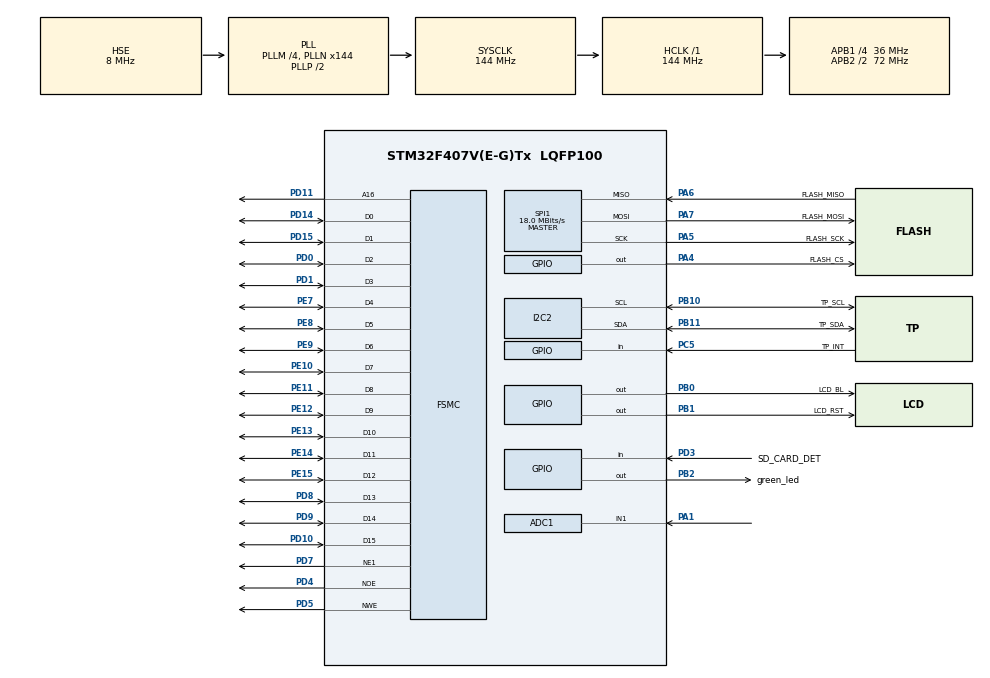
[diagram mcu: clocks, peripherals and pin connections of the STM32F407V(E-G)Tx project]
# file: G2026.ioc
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ADC1.Channel-1\#ChannelRegularConversion=ADC_CHANNEL_1
ADC1.DMAContinuousRequests=ENABLE
ADC1.ExternalTrigConv=ADC_EXTERNALTRIGCONV_T8_TRGO
ADC1.NbrOfConversionFlag=1
ADC1.Rank-1\#ChannelRegularConversion=1
ADC1.SamplingTime-1\#ChannelRegularConversion=ADC_SAMPLETIME_3CYCLES
ADC1.master=1
Dma.ADC1.0.Direction=DMA_PERIPH_TO_MEMORY
Dma.ADC1.0.FIFOMode=DMA_FIFOMODE_DISABLE
Dma.ADC1.0.Instance=DMA2_Stream0
Dma.ADC1.0.MemDataAlignment=DMA_MDATAALIGN_HALFWORD
Dma.ADC1.0.MemInc=DMA_MINC_ENABLE
Dma.ADC1.0.Mode=DMA_CIRCULAR
Dma.ADC1.0.PeriphDataAlignment=DMA_PDATAALIGN_HALFWORD
Dma.ADC1.0.PeriphInc=DMA_PINC_DISABLE
Dma.ADC1.0.Priority=DMA_PRIORITY_HIGH
Dma.Request0=ADC1
FREERTOS.Tasks01=defaultTask,24,256,StartDefaultTask,Default,NULL,Dynamic,NULL,NULL
FREERTOS.configTOTAL_HEAP_SIZE=4096
FSMC.AddressSetupTime1=2
FSMC.BusTurnAroundDuration1=0
FSMC.DataSetupTime1=8
FSMC.WriteOperation1=FSMC_WRITE_OPERATION_ENABLE
I2C2.I2C_Mode=I2C_Standard
Mcu.Family=STM32F4
Mcu.Name=STM32F407V(E-G)Tx
Mcu.Package=LQFP100
NVIC.DMA2_Stream0_IRQn=true\:5\:0\:false\:false\:true\:true\:false\:true\:true
NVIC.PriorityGroup=NVIC_PRIORITYGROUP_4
NVIC.TIM6_DAC_IRQn=true\:15\:0\:false\:false\:true\:false\:true\:true\:true
NVIC.TimeBase=TIM6_DAC_IRQn
NVIC.TimeBaseIP=TIM6
PA1.Signal=ADCx_IN1
PA13.GPIO_Label=SWDIO
PA13.Mode=Serial_Wire
PA13.Signal=SYS_JTMS-SWDIO
PA14.GPIO_Label=SWCLK
PA14.Mode=Serial_Wire
PA14.Signal=SYS_JTCK-SWCLK
PA4.GPIO_Label=FLASH_CS
PA4.PinState=GPIO_PIN_SET
PA4.Signal=GPIO_Output
PA5.GPIO_Label=FLASH_SCK
PA5.Mode=Full_Duplex_Master
PA5.Signal=SPI1_SCK
PA6.GPIO_Label=FLASH_MISO
PA6.Mode=Full_Duplex_Master
PA6.Signal=SPI1_MISO
PA7.GPIO_Label=FLASH_MOSI
PA7.Mode=Full_Duplex_Master
PA7.Signal=SPI1_MOSI
PB0.GPIO_Label=LCD_BL
PB0.PinState=GPIO_PIN_RESET
PB0.Signal=GPIO_Output
PB1.GPIO_Label=LCD_RST
PB1.PinState=GPIO_PIN_SET
PB1.Signal=GPIO_Output
PB10.GPIO_Label=TP_SCL
PB10.Mode=I2C
PB10.Signal=I2C2_SCL
PB11.GPIO_Label=TP_SDA
PB11.Mode=I2C
PB11.Signal=I2C2_SDA
PB2.GPIO_Label=green_led
PB2.PinState=GPIO_PIN_RESET
PB2.Signal=GPIO_Output
PC14-OSC32_IN.GPIO_Label=LSE_IN
PC14-OSC32_IN.Mode=LSE-External-Oscillator
PC14-OSC32_IN.Signal=RCC_OSC32_IN
PC15-OSC32_OUT.GPIO_Label=LSE_OUT
PC15-OSC32_OUT.Mode=LSE-External-Oscillator
PC15-OSC32_OUT.Signal=RCC_OSC32_OUT
PC5.GPIO_Label=TP_INT
PC5.GPIO_PuPd=GPIO_PULLUP
PC5.Signal=GPIO_Input
PD0.Mode=16b-d1
PD0.Signal=FSMC_D2
PD1.Mode=16b-d1
PD1.Signal=FSMC_D3
PD10.Mode=16b-d1
PD10.Signal=FSMC_D15
PD11.Mode=A16_1
PD11.Signal=FSMC_A16
PD14.Mode=16b-d1
PD14.Signal=FSMC_D0
PD15.Mode=16b-d1
PD15.Signal=FSMC_D1
PD3.GPIO_Label=SD_CARD_DET
PD3.GPIO_PuPd=GPIO_PULLUP
PD3.Signal=GPIO_Input
PD4.Mode=Lcd1
PD4.Signal=FSMC_NOE
PD5.Mode=Lcd1
PD5.Signal=FSMC_NWE
PD7.Mode=NorPsramChipSelect1_1
PD7.Signal=FSMC_NE1
PD8.Mode=16b-d1
PD8.Signal=FSMC_D13
PD9.Mode=16b-d1
PD9.Signal=FSMC_D14
PE10.Mode=16b-d1
PE10.Signal=FSMC_D7
PE11.Mode=16b-d1
PE11.Signal=FSMC_D8
PE12.Mode=16b-d1
PE12.Signal=FSMC_D9
PE13.Mode=16b-d1
PE13.Signal=FSMC_D10
PE14.Mode=16b-d1
PE14.Signal=FSMC_D11
PE15.Mode=16b-d1
PE15.Signal=FSMC_D12
PE7.Mode=16b-d1
PE7.Signal=FSMC_D4
PE8.Mode=16b-d1
PE8.Signal=FSMC_D5
PE9.Mode=16b-d1
PE9.Signal=FSMC_D6
PH0-OSC_IN.GPIO_Label=HSE_IN
PH0-OSC_IN.Mode=HSE-External-Oscillator
PH0-OSC_IN.Signal=RCC_OSC_IN
PH1-OSC_OUT.GPIO_Label=HSE_OUT
PH1-OSC_OUT.Mode=HSE-External-Oscillator
PH1-OSC_OUT.Signal=RCC_OSC_OUT
ProjectManager.HeapSize=0x200
ProjectManager.StackSize=0x400
ProjectManager.TargetToolchain=CMake
RCC.48MHZClocksFreq_Value=48000000
RCC.AHBFreq_Value=144000000
RCC.APB1CLKDivider=RCC_HCLK_DIV4
RCC.APB1Freq_Value=36000000
RCC.APB1TimFreq_Value=72000000
RCC.APB2CLKDivider=RCC_HCLK_DIV2
RCC.APB2Freq_Value=72000000
RCC.APB2TimFreq_Value=144000000
RCC.CortexFreq_Value=144000000
RCC.HCLKFreq_Value=144000000
RCC.HSE_VALUE=8000000
RCC.HSI_VALUE=16000000
RCC.PLLM=4
RCC.PLLN=144
RCC.PLLQ=6
RCC.PLLSourceVirtual=RCC_PLLSOURCE_HSE
RCC.RCC_RTC_Clock_SourceVirtual=RCC_RTCCLKSOURCE_LSE
RCC.RTCClockSelection=RCC_RTCCLKSOURCE_LSE
RCC.RTCClockSelectionARG=RCC_RTCCLKSOURCE_LSE
RCC.SYSCLKFreq_VALUE=144000000
RCC.SYSCLKSource=RCC_SYSCLKSOURCE_PLLCLK
RCC.VCOOutputFreq_Value=288000000
SH.ADCx_IN1.0=ADC1_IN1,IN1
SPI1.BaudRatePrescaler=SPI_BAUDRATEPRESCALER_4
SPI1.CalculateBaudRate=18.0 MBits/s
SPI1.Direction=SPI_DIRECTION_2LINES
SPI1.Mode=SPI_MODE_MASTER
SPI1.VirtualType=VM_MASTER
STMicroelectronics.X-CUBE-ALGOBUILD.1.5.0.LibraryCcDSPOoLibraryJjDSPOoLibrary=true
TIM8.ClockDivision=TIM_CLOCKDIVISION_DIV1
TIM8.CounterMode=TIM_COUNTERMODE_UP
TIM8.Period=71
TIM8.Prescaler=0
TIM8.TIM_MasterOutputTrigger=TIM_TRGO_UPDATE
VP_FREERTOS_VS_CMSIS_V2.Mode=CMSIS_V2
VP_RTC_VS_RTC_Activate.Mode=RTC_Enabled
VP_STMicroelectronics.X-CUBE-ALGOBUILD_VS_DSPOoLibraryJjLibrary_1.5.0_1.5.0.Mode=DSPOoLibraryJjLibrary
VP_SYS_VS_tim6.Mode=TIM6
VP_TIM8_VS_ClockSourceINT.Mode=Internal
board=custom

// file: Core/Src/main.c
/* USER CODE BEGIN Header */
/**
  ******************************************************************************
  * @file           : main.c
  * @brief          : Main program body
  ******************************************************************************
  * @attention
  *
  * Copyright (c) 2026 STMicroelectronics.
  * All rights reserved.
  *
  * This software is licensed under terms that can be found in the LICENSE file
  * in the root directory of this software component.
  * If no LICENSE file comes with this software, it is provided AS-IS.
  *
  ******************************************************************************
  */
/* USER CODE END Header */
#include "main.h"
#include "cmsis_os.h"
#include "adc.h"
#include "dma.h"
#include "i2c.h"
#include "rtc.h"
#include "spi.h"
#include "tim.h"
#include "gpio.h"
#include "fsmc.h"

/* USER CODE BEGIN Includes */
/* ★ 程序入口。main() 属于 Core/（生成物），它是"启动序列"而不是四层里的一层，
 *   所以"Core 调 Task"不算越层（docs/01 §组合根）。
 *   规矩：这里**只写胶水**，任何逻辑都回 Task/ 层。 */
#include "app.h" /* Task 层：app_init() —— 组合根 */
/* USER CODE END Includes */

void SystemClock_Config(void);
void MX_FREERTOS_Init(void);

int main(void)
{

  /* MCU Configuration--------------------------------------------------------*/

  /* Reset of all peripherals, Initializes the Flash interface and the Systick. */
  HAL_Init();

  /* Configure the system clock */
  SystemClock_Config();

  /* Initialize all configured peripherals */
  MX_GPIO_Init();
  MX_DMA_Init();
  MX_SPI1_Init();
  MX_RTC_Init();
  MX_TIM8_Init();
  MX_I2C2_Init();
  MX_ADC1_Init();
  MX_FSMC_Init();
  /* USER CODE BEGIN 2 */
  /* ★ 全工程唯一的应用入口。
   *
   * 为什么放在这里（时序上必须是这个位置）：
   *   HAL_Init → SystemClock_Config → MX_*_Init 已完成，硬件都就位了；
   *   而 osKernelInitialize / MX_FREERTOS_Init / osKernelStart 还没调 ——
   *   ⇒ app_init() 运行时**调度器还没启动**，所以它里面不许取任何
   *     FreeRTOS 原语（锁 / 队列 / 延时）。详见 Task/Inc/app.h 的时序说明。
   *
   * ⚠️ 这是 main.c 里唯一该出现的一行业务代码。要加功能就进 Task/ 层。 */
  app_init();
  /* USER CODE END 2 */

  /* Init scheduler */
  osKernelInitialize();  /* Call init function for freertos objects (in cmsis_os2.c) */
  MX_FREERTOS_Init();

  /* Start scheduler */
  osKernelStart();

  /* We should never get here as control is now taken by the scheduler */

  /* Infinite loop */
  while (1)
  {

  }
}

void SystemClock_Config(void)
{
  RCC_OscInitTypeDef RCC_OscInitStruct = {0};
  RCC_ClkInitTypeDef RCC_ClkInitStruct = {0};

  /** Configure the main internal regulator output voltage
  */
  __HAL_RCC_PWR_CLK_ENABLE();
  __HAL_PWR_VOLTAGESCALING_CONFIG(PWR_REGULATOR_VOLTAGE_SCALE1);

  /** Initializes the RCC Oscillators according to the specified parameters
  * in the RCC_OscInitTypeDef structure.
  */
  RCC_OscInitStruct.OscillatorType = RCC_OSCILLATORTYPE_HSE|RCC_OSCILLATORTYPE_LSE;
  RCC_OscInitStruct.HSEState = RCC_HSE_ON;
  RCC_OscInitStruct.LSEState = RCC_LSE_ON;
  RCC_OscInitStruct.PLL.PLLState = RCC_PLL_ON;
  RCC_OscInitStruct.PLL.PLLSource = RCC_PLLSOURCE_HSE;
  RCC_OscInitStruct.PLL.PLLM = 4;
  RCC_OscInitStruct.PLL.PLLN = 144;
  RCC_OscInitStruct.PLL.PLLP = RCC_PLLP_DIV2;
  RCC_OscInitStruct.PLL.PLLQ = 6;
  if (HAL_RCC_OscConfig(&RCC_OscInitStruct) != HAL_OK)
  {
    Error_Handler();
  }

  /** Initializes the CPU, AHB and APB buses clocks
  */
  RCC_ClkInitStruct.ClockType = RCC_CLOCKTYPE_HCLK|RCC_CLOCKTYPE_SYSCLK
                              |RCC_CLOCKTYPE_PCLK1|RCC_CLOCKTYPE_PCLK2;
  RCC_ClkInitStruct.SYSCLKSource = RCC_SYSCLKSOURCE_PLLCLK;
  RCC_ClkInitStruct.AHBCLKDivider = RCC_SYSCLK_DIV1;
  RCC_ClkInitStruct.APB1CLKDivider = RCC_HCLK_DIV4;
  RCC_ClkInitStruct.APB2CLKDivider = RCC_HCLK_DIV2;

  if (HAL_RCC_ClockConfig(&RCC_ClkInitStruct, FLASH_LATENCY_4) != HAL_OK)
  {
    Error_Handler();
  }
}

void HAL_TIM_PeriodElapsedCallback(TIM_HandleTypeDef *htim)
{
  if (htim->Instance == TIM6)
  {
    HAL_IncTick();
  }
}

void Error_Handler(void)
{
  /* USER CODE BEGIN Error_Handler_Debug */
  /* ★ CubeMX 的默认实现是 `__disable_irq(); while(1);` —— **完全无声**。
   *   那时的现象是"板子毫无反应、RTT 一个字都没有"，与"固件没烧进去"
   *   "探针没插"完全无法区分 —— 实测能白查半小时。
   *   ⇒ 至少要把日志后端拉起来（RTT 只要内存，不需要时钟与中断）打一行。
   *
   * ⚠️ 但**不能**走"停机"路径 —— 2026-09-23 上板实测：
   *    Error_Handler 会被**所有** HAL 初始化失败调到，其中最常见的是
   *    `MX_SDIO_SD_Init()`：**板子上没插 TF 卡时 `HAL_SD_Init()` 必然失败**，
   *    结果整块板子起不来。实测调用栈：
   *      Reset_Handler → main → MX_SDIO_SD_Init → Error_Handler → 停机
   *    TF 卡是可选外设，不该绑架启动。
   *
   * ⇒ 改成 app_init_failed()：打一行 ERROR 日志后**返回**，让 main() 继续。
   *   （它故意不打 [AI_FAIL] 标记 —— 那是 fw.py verify 的失败判据，
   *     打了会把"其实跑起来了"误判成失败。） */
  app_init_failed("Error_Handler: HAL 初始化未成功（外设？时钟？HSE 起振？）");
  /* USER CODE END Error_Handler_Debug */
}

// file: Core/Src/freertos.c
/* USER CODE BEGIN Header */
/**
  ******************************************************************************
  * File Name          : freertos.c
  * Description        : Code for freertos applications
  ******************************************************************************
  * @attention
  *
  * Copyright (c) 2026 STMicroelectronics.
  * All rights reserved.
  *
  * This software is licensed under terms that can be found in the LICENSE file
  * in the root directory of this software component.
  * If no LICENSE file comes with this software, it is provided AS-IS.
  *
  ******************************************************************************
  */
/* USER CODE END Header */

#include "FreeRTOS.h"
#include "task.h"
#include "main.h"
#include "cmsis_os.h"

/* USER CODE BEGIN Includes */
/* ★ 本文件在 `Core/` 下（最底层、CubeMX 生成物），它是**程序入口**而不是
 *   四层里的一层 —— 所以"Core 调 Task"不算越层（docs/01 §组合根）。
 *   规矩：这里**只写胶水**，任何逻辑都回 Task/ 层。
 *
 * 注意只需要 app_rtos.h：初始化由 main.c 的 app_init() 负责（时序见 app.h）。 */
#include "app_rtos.h"
/* USER CODE END Includes */

/* Definitions for defaultTask */
osThreadId_t defaultTaskHandle;
const osThreadAttr_t defaultTask_attributes = {
  .name = "defaultTask",
  .stack_size = 256 * 4,
  .priority = (osPriority_t) osPriorityNormal,
};

void StartDefaultTask(void *argument);

void MX_FREERTOS_Init(void); /* (MISRA C 2004 rule 8.1) */

void MX_FREERTOS_Init(void) {

  /* Create the thread(s) */
  /* creation of defaultTask */
  defaultTaskHandle = osThreadNew(StartDefaultTask, NULL, &defaultTask_attributes);

  /* USER CODE BEGIN RTOS_THREADS */
  /* add threads, ... */
  /* ★ 这里**故意是空的**。理由（实测）：CubeMX 会强制重建 defaultTask 与
   *   StartDefaultTask —— 在 .ioc 里清空 FREERTOS.IPParameters、删掉 Tasks01
   *   后重新生成，它照样补回来。所以不跟它斗：
   *       本任务（defaultTask）就是本工程的**唯一周期任务**，
   *       它的栈深 / 优先级在 .ioc 的 FREERTOS.Tasks01 里给（256 words / 优先级 24），
   *       循环体在 Task/Src/app_rtos.c 的 app_rtos_run()。
   *   ⇒ 加新任务时，在 Task/ 层用 xTaskCreate 建，参数写进 project_config.h。
   *     不要在这里建 —— 这是生成物（docs/01 规矩 4）。 */
  /* USER CODE END RTOS_THREADS */

}

void StartDefaultTask(void *argument)
{
  /* USER CODE BEGIN StartDefaultTask */
  (void)argument; /* 未使用参数：显式标注，否则 -Wextra 会报 */

  /* ★ 只留一行胶水：循环体、节拍、将来的多任务划分全在 Task/ 层。
   *   这样"改调度"不用碰生成物，也不会被下次 CubeMX 生成冲掉。
   *   ⚠️ app_rtos_run() **不返回** —— 返回等于把生成物的 osDelay(1) 空转循环
   *      跑起来，那是另一套节拍了。 */
  app_rtos_run();
  /* USER CODE END StartDefaultTask */
}
